# ATSAMC21N18A register map
Registers from a debugger description file.
Registers are 32-bit, access not given, no defined reset value unless marked. A register's access mark holds for its fields unless they carry their own. Addresses are absolute; registers are grouped by the start of their names; lines under a group give offsets from that group; [hi:lo] are bit positions; {n}, {i} and the like mark numbered series; 'fields as' and 'values as' point back to an identical list; <NAME> marks a mode.

## Further device data
memory=FLASH Memory 0x00000000 0x0003FFFF RW; RWW Memory 0x00400000 0x00401FFF RW; CAL Memory 0x00800000 0x00800007 R; LOCKBIT Memory 0x00802000 0x00802003 R; USER_PAGE Memory 0x00804000 0x008040FF RW; OTP1 Memory 0x00806000 0x00806007 R; OTP2 Memory 0x00806008 0x0080600F R; OTP3 Memory 0x00806010 0x00806017 R; OTP4 Memory 0x00806018 0x0080601F R; OTP5 Memory 0x00806020 0x00806027 R; TEMP_LOG Memory 0x00806030 0x00806037 R; HSRAM Memory 0x20000000 0x20007FFF RW; HPB0 Memory 0x40000000 0x40003FFF RW; PERIPHERALS Memory 0x40000000 0x5FFFFFFF RW; HPB1 Memory 0x41000000 0x4100FFFF RW; HPB2 Memory 0x42000000 0x42007FFF RW; HPB3 Memory 0x43000000 0x43007FFF RW; DIVAS Memory 0x48000000 0x4800001F RW; PPB Memory 0xE0000000 0xE00FFFFF RW; SCS Memory 0xE000E000 0xE000EFFF RW, interrupts=SYSTEM 0x0; WDT 0x1; RTC 0x2; EIC 0x3; FREQM 0x4; TSENS 0x5; NVMCTRL 0x6; DMAC 0x7; EVSYS 0x8; SERCOM0_6 0x9; SERCOM1_7 0xA; SERCOM2 0xB; SERCOM3 0xC; SERCOM4 0xD; SERCOM5 0xE; CAN0 0xF; CAN1 0x10; TCC0 0x11; TCC1 0x12; TCC2 0x13; TC0_5 0x14; TC1_6 0x15; TC2_7 0x16; TC3 0x17; TC4 0x18; ADC0 0x19; ADC1 0x1A; AC 0x1B; DAC 0x1C; SDADC 0x1D; PTC 0x1E

## AC
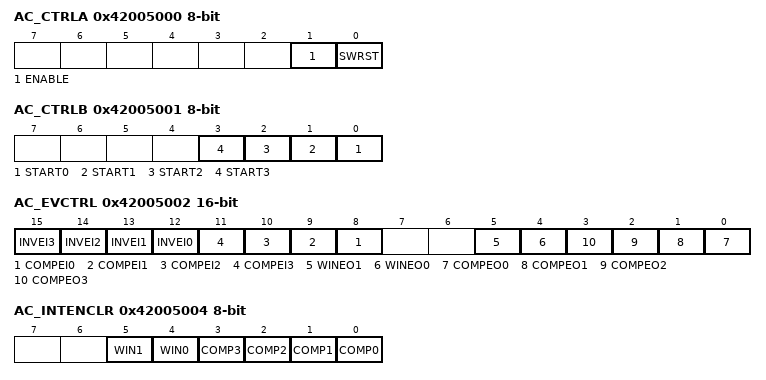
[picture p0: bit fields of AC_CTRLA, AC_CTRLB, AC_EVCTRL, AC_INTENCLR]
0x42005000 AC_CTRLA 8-bit — Control A
  [1] ENABLE, [0] SWRST
0x42005001 AC_CTRLB 8-bit — Control B
  [n] START{n} (n=0..3)
0x42005002 AC_EVCTRL 16-bit — Event Control
  [n+12] INVEI{n} (n=0..3), [n+8] COMPEI{n} (n=0..3), [5] WINEO1, [4] WINEO0, [n] COMPEO{n} (n=0..3)
0x42005004 AC_INTENCLR 8-bit — Interrupt Enable Clear
  [5] WIN1, [4] WIN0, [n] COMP{n} (n=0..3)
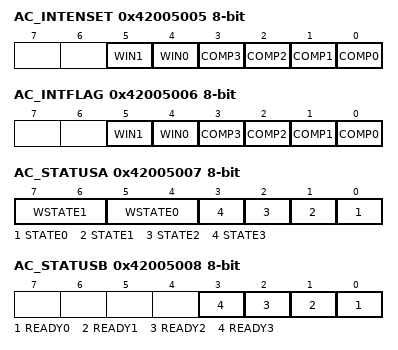
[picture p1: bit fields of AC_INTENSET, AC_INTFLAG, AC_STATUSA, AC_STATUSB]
0x42005005 AC_INTENSET 8-bit — Interrupt Enable Set
  [5] WIN1, [4] WIN0, [n] COMP{n} (n=0..3)
0x42005006 AC_INTFLAG 8-bit — Interrupt Flag Status and Clear
  [5] WIN1, [4] WIN0, [n] COMP{n} (n=0..3)
0x42005007 AC_STATUSA 8-bit — Status A
  [7:6] WSTATE1, [5:4] WSTATE0, [n] STATE{n} (n=0..3)
0x42005008 AC_STATUSB 8-bit — Status B
  [n] READY{n} (n=0..3)
0x42005009 AC_DBGCTRL 8-bit — Debug Control
  [0] DBGRUN
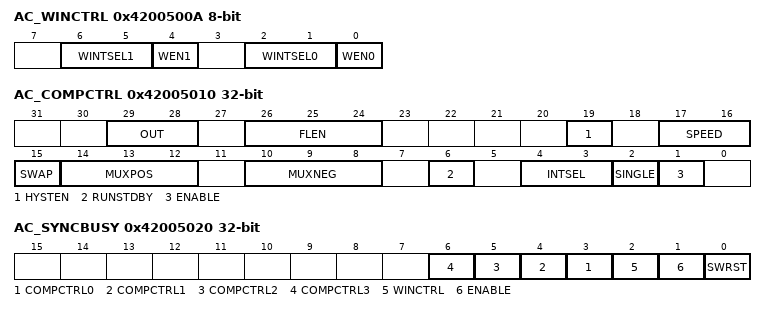
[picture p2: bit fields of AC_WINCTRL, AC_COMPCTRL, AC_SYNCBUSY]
0x4200500A AC_WINCTRL 8-bit — Window Control
  [6:5] WINTSEL1, [4] WEN1, [2:1] WINTSEL0, [0] WEN0
0x4200500C AC_SCALER 8-bit — Scaler n
  [5:0] VALUE
0x42005010 AC_COMPCTRL — Comparator Control n
  [29:28] OUT, [26:24] FLEN, [19] HYSTEN, [17:16] SPEED, [15] SWAP, [14:12] MUXPOS, [10:8] MUXNEG, [6] RUNSTDBY, [4:3] INTSEL, [2] SINGLE, [1] ENABLE
0x42005020 AC_SYNCBUSY — Synchronization Busy
  [n+3] COMPCTRL{n} (n=0..3), [2] WINCTRL, [1] ENABLE, [0] SWRST

## ADC0
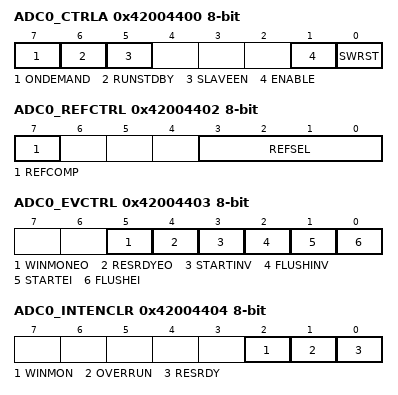
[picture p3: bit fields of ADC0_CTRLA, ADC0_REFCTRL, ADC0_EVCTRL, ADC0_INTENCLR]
0x42004400 ADC0_CTRLA 8-bit — Control A
  [7] ONDEMAND, [6] RUNSTDBY, [5] SLAVEEN, [1] ENABLE, [0] SWRST
0x42004401 ADC0_CTRLB 8-bit — Control B
  [2:0] PRESCALER
0x42004402 ADC0_REFCTRL 8-bit — Reference Control
  [7] REFCOMP, [3:0] REFSEL
0x42004403 ADC0_EVCTRL 8-bit — Event Control
  [5] WINMONEO, [4] RESRDYEO, [3] STARTINV, [2] FLUSHINV, [1] STARTEI, [0] FLUSHEI
0x42004404 ADC0_INTENCLR 8-bit — Interrupt Enable Clear
  [2] WINMON, [1] OVERRUN, [0] RESRDY
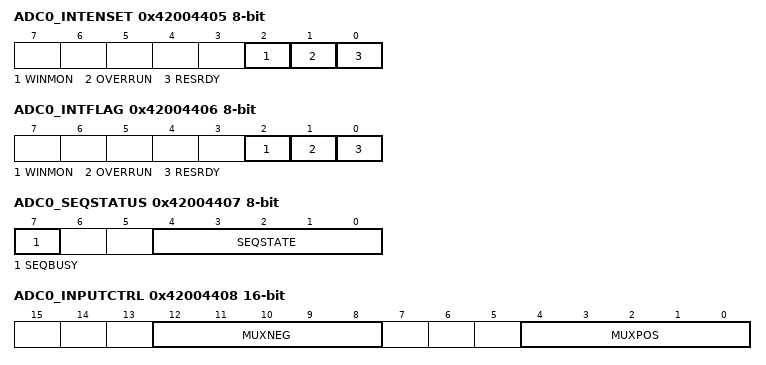
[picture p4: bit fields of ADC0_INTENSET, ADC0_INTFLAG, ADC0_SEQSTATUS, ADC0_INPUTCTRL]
0x42004405 ADC0_INTENSET 8-bit — Interrupt Enable Set
  [2] WINMON, [1] OVERRUN, [0] RESRDY
0x42004406 ADC0_INTFLAG 8-bit — Interrupt Flag Status and Clear
  [2] WINMON, [1] OVERRUN, [0] RESRDY
0x42004407 ADC0_SEQSTATUS 8-bit — Sequence Status
  [7] SEQBUSY, [4:0] SEQSTATE
0x42004408 ADC0_INPUTCTRL 16-bit — Input Control
  [12:8] MUXNEG, [4:0] MUXPOS
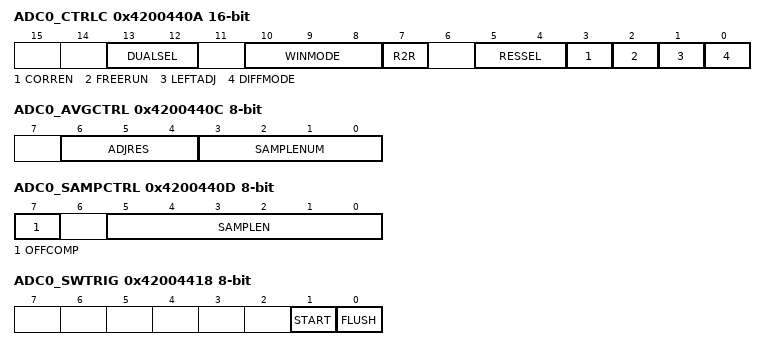
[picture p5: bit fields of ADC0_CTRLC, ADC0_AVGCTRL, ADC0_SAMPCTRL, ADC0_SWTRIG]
0x4200440A ADC0_CTRLC 16-bit — Control C
  [13:12] DUALSEL, [10:8] WINMODE, [7] R2R, [5:4] RESSEL, [3] CORREN, [2] FREERUN, [1] LEFTADJ, [0] DIFFMODE
0x4200440C ADC0_AVGCTRL 8-bit — Average Control
  [6:4] ADJRES, [3:0] SAMPLENUM
0x4200440D ADC0_SAMPCTRL 8-bit — Sample Time Control
  [7] OFFCOMP, [5:0] SAMPLEN
0x4200440E ADC0_WINLT 16-bit — Window Monitor Lower Threshold
0x42004410 ADC0_WINUT 16-bit — Window Monitor Upper Threshold
0x42004412 ADC0_GAINCORR 16-bit — Gain Correction
  [11:0] GAINCORR
0x42004414 ADC0_OFFSETCORR 16-bit — Offset Correction
  [11:0] OFFSETCORR
0x42004418 ADC0_SWTRIG 8-bit — Software Trigger
  [1] START, [0] FLUSH
0x4200441C ADC0_DBGCTRL 8-bit — Debug Control
  [0] DBGRUN
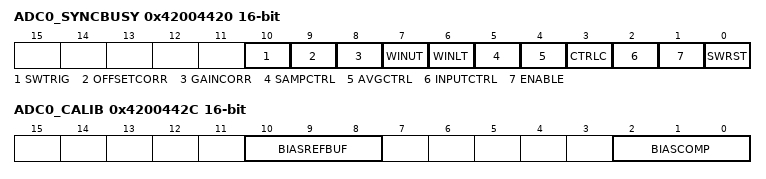
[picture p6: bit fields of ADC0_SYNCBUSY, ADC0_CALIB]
0x42004420 ADC0_SYNCBUSY 16-bit — Synchronization Busy
  [10] SWTRIG, [9] OFFSETCORR, [8] GAINCORR, [7] WINUT, [6] WINLT, [5] SAMPCTRL, [4] AVGCTRL, [3] CTRLC, [2] INPUTCTRL, [1] ENABLE, [0] SWRST
0x42004424 ADC0_RESULT 16-bit — Result
0x42004428 ADC0_SEQCTRL — Sequence Control
  [31:0] SEQEN
0x4200442C ADC0_CALIB 16-bit — Calibration
  [10:8] BIASREFBUF, [2:0] BIASCOMP
